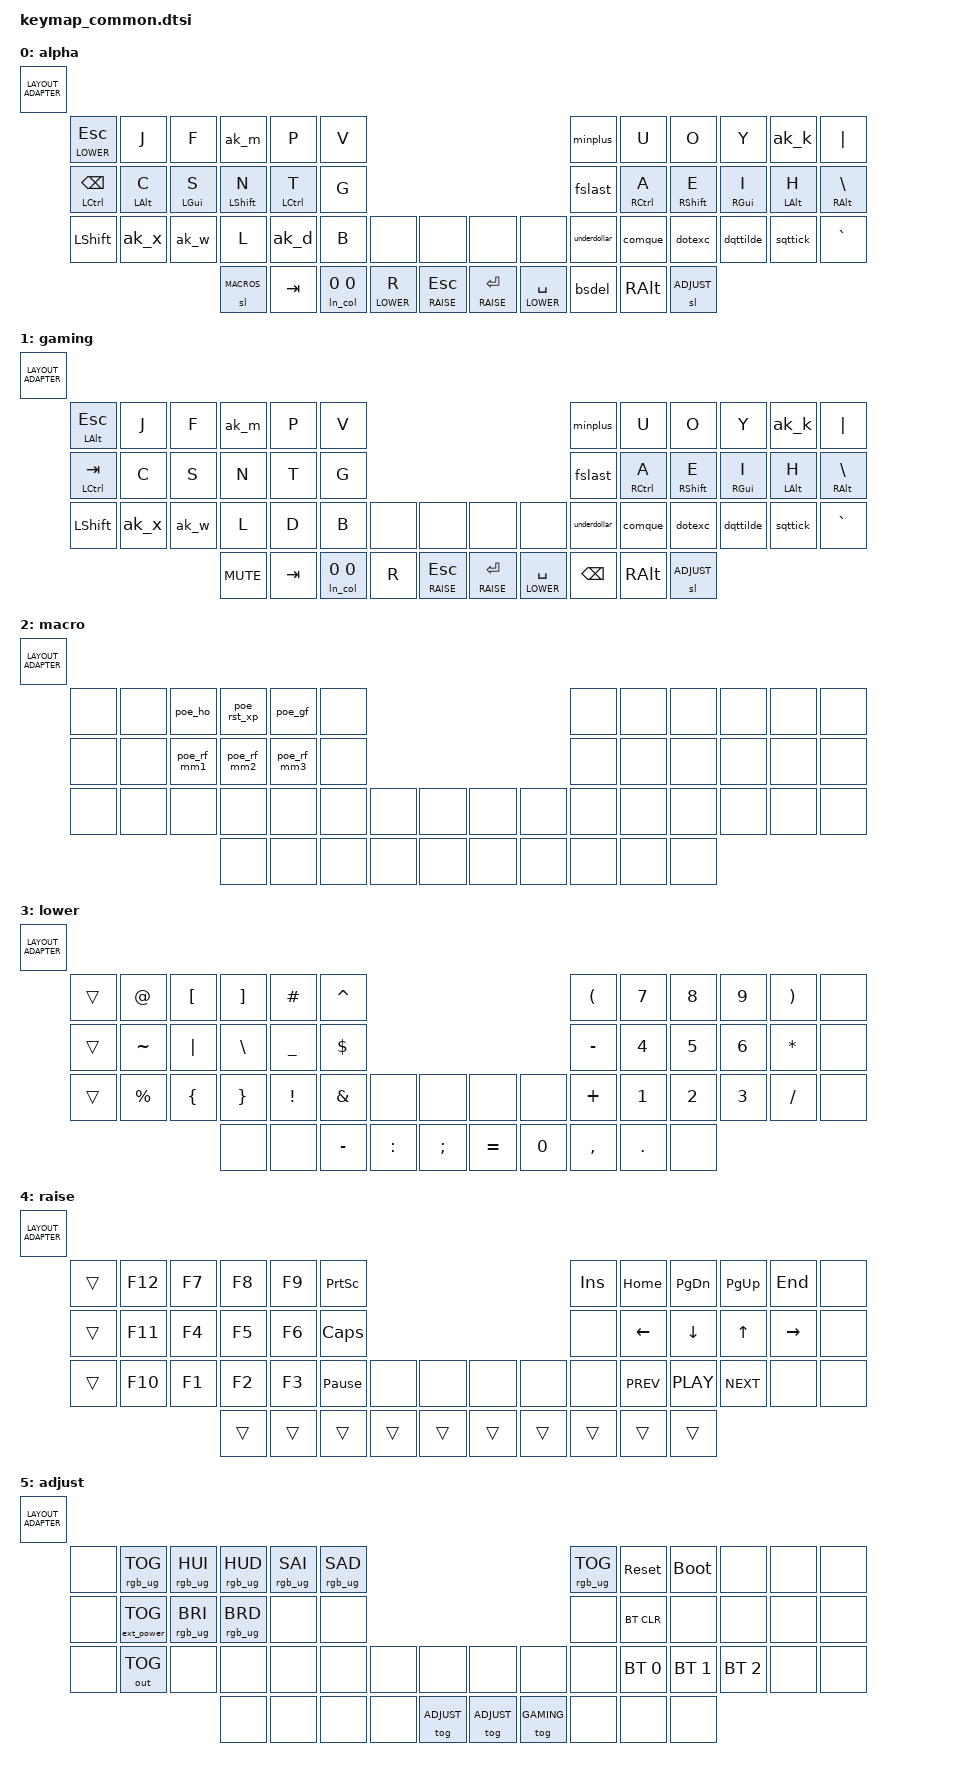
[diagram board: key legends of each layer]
#include "adaptive_keys.dtsi"
#include "behaviors_custom.dtsi"
#include "combos.dtsi"
#include "macros.dtsi"
#include "layer_ids.h"

#include <behaviors.dtsi>
#include <dt-bindings/zmk/bt.h>
#include <dt-bindings/zmk/ext_power.h>
#include <dt-bindings/zmk/keys.h>
#include <dt-bindings/zmk/outputs.h>
#include <dt-bindings/zmk/rgb.h>

// Configure these properties here to ensure they are set after the last time behaviors.dtsi is included, since that
// resets them to their default values.
&mt {
    tapping-term-ms = <170>;
};

&sl {
    release-after-ms = <5000>;
};

/ {
    keymap {
        compatible = "zmk,keymap";

        default_layer {
            display-name = "alpha";
            // -------------------------------------------------------------------------------------------------------------------------------------
            // |   ESC  |  J  |  F  |   M   |  P   |  V   |                                          |  - + |   U   |   O   |  Y   |   K   |   |  |
            // | L CTRL |  C  |  S  |   N   |  T   |  G   |                                          |  / * |   A   |   E   |  I   |   H   |   \  |
            // |  SHIFT |  X  |  W  |   L   |  D   |  B   |  NONE   |   NONE  |  |   NONE  |  NONE   |  _ $ |  , ?  |  . !  |  " ~ |  ' `  | ` ~  |
            //                      | MACROS| TAB  | : ;  |   R     |   ESC   |  |   RET   |  SPACE  | BSPC | R ALT |  NONE |
            bindings = <LAYOUT_ADAPTER(
                &lt LOWER ESC,  &kp J,       &kp F,       &ak_m,        &kp P,        &kp V,                                                                    &minplus,     &kp U,        &kp O,        &kp Y,       &ak_k,       &kp PIPE,
                &mt LCTRL BSPC, &hml LALT C, &hml LGUI S, &hml LSHFT N, &hml LCTRL T, &kp G,                                                                    &fslast,      &hmr RCTRL A, &hmr RSHFT E, &hmr RGUI I, &hmr LALT H, &hmr RALT BSLH,
                &kp LSHFT,      &ak_x,       &ak_w,       &kp L,        &ak_d,        &kp B,       &none,       &none,          &none,         &none,           &underdollar, &comque,      &dotexc,      &dqttilde,   &sqttick,    &kp GRAVE,
                                                          &sl MACROS,   &kp TAB,      &ln_col 0 0, &lt LOWER R, &lt RAISE ESC,  &lt RAISE RET, &lt LOWER SPACE, &bsdel,       &kp RALT,     &sl ADJUST
            )>;

            sensor-bindings = <&inc_dec_kp PG_UP PG_DN &inc_dec_kp C_VOL_DN C_VOL_UP>;
    };

        gaming_layer {
            display-name = "gaming";
            bindings = <LAYOUT_ADAPTER(
                &mt LALT ESC,  &kp J, &kp F, &ak_m,      &kp P,   &kp V,                                                              &minplus,     &kp U,         &kp O,        &kp Y,       &ak_k,       &kp PIPE,
                &mt LCTRL TAB, &kp C, &kp S, &kp N,      &kp T,   &kp G,                                                              &fslast,      &hmr RCTRL A,  &hmr RSHFT E, &hmr RGUI I, &hmr LALT H, &hmr RALT BSLH,
                &kp LSHFT,     &ak_x, &ak_w, &kp L,      &kp D,   &kp B,       &none, &none,          &none,         &none,           &underdollar, &comque,       &dotexc,      &dqttilde,   &sqttick,    &kp GRAVE,
                                             &kp C_MUTE, &kp TAB, &ln_col 0 0, &kp R, &lt RAISE ESC,  &lt RAISE RET, &lt LOWER SPACE, &kp BSPC,     &kp RALT,      &sl ADJUST
            )>;

            sensor-bindings = <&inc_dec_kp PG_UP PG_DN &inc_dec_kp C_VOL_DN C_VOL_UP>;
        };

        macro_layer {
            display-name = "macro";
            bindings = <LAYOUT_ADAPTER(
                &none, &none, &poe_ho,     &poe_rst_xp, &poe_gf,     &none,                              &none, &none, &none, &none, &none, &none,
                &none, &none, &poe_rf_mm1, &poe_rf_mm2, &poe_rf_mm3, &none,                              &none, &none, &none, &none, &none, &none,
                &none, &none, &none,       &none,       &none,       &none, &none, &none,  &none, &none, &none, &none, &none, &none, &none, &none,
                                           &none,       &none,       &none, &none, &none,  &none, &none, &none, &none, &none
            )>;
        };

        lower_layer {
            display-name = "lower";
            bindings = <LAYOUT_ADAPTER(
                &trans, &kp AT,    &kp LBKT, &kp RBKT, &kp HASH,  &kp CARET,                                          &kp LPAR,  &kp N7,  &kp N8, &kp N9, &kp RPAR,  &none,
                &trans, &kp TILDE, &kp PIPE, &kp BSLH, &kp UNDER, &kp DLLR,                                           &kp MINUS, &kp N4,  &kp N5, &kp N6, &kp ASTRK, &none,
                &trans, &kp PRCNT, &kp LBRC, &kp RBRC, &kp EXCL,  &kp AMPS,  &none,     &none,     &none,     &none,  &kp PLUS,  &kp N1,  &kp N2, &kp N3, &kp FSLH,  &none,
                                             &none,    &none,     &kp MINUS, &kp COLON, &kp SEMI,  &kp EQUAL, &kp N0, &kp COMMA, &kp DOT, &none
            )>;

            sensor-bindings = <&inc_dec_kp PG_UP PG_DN &inc_dec_kp C_VOL_DN C_VOL_UP>;
        };

        raise_layer {
            display-name = "raise";
            bindings = <LAYOUT_ADAPTER(
                &trans, &kp F12, &kp F7, &kp F8, &kp F9, &kp PSCRN,                                         &kp INS, &kp HOME,   &kp PG_DN,  &kp PG_UP,  &kp END,   &none,
                &trans, &kp F11, &kp F4, &kp F5, &kp F6, &kp CAPS,                                          &none,   &kp LEFT,   &kp DOWN,   &kp UP,     &kp RIGHT, &none,
                &trans, &kp F10, &kp F1, &kp F2, &kp F3, &kp PAUSE_BREAK, &none,   &none,   &none,  &none,  &none,   &kp C_PREV, &kp C_PLAY, &kp C_NEXT, &none,     &none,
                                         &trans, &trans, &trans,          &trans,  &trans,  &trans, &trans, &trans,  &trans,     &trans
            )>;

            sensor-bindings = <&inc_dec_kp PG_UP PG_DN &inc_dec_kp C_VOL_DN C_VOL_UP>;
        };

        adjust_layer {
            display-name = "adjust";
            bindings = <LAYOUT_ADAPTER(
                &none, &rgb_ug RGB_TOG,   &rgb_ug RGB_HUI, &rgb_ug RGB_HUD, &rgb_ug RGB_SAI, &rgb_ug RGB_SAD,                                                 &rgb_ug RGB_TOG, &sys_reset,   &bootloader,  &none,        &none, &none,
                &none, &ext_power EP_TOG, &rgb_ug RGB_BRI, &rgb_ug RGB_BRD, &none,           &none,                                                           &none,           &bt BT_CLR,   &none,        &none,        &none, &none,
                &none, &out OUT_TOG,      &none,           &none,           &none,           &none,           &none, &none,        &none,       &none,        &none,           &bt BT_SEL 0, &bt BT_SEL 1, &bt BT_SEL 2, &none, &none,
                                                           &none,           &none,           &none,           &none, &tog ADJUST,  &tog ADJUST, &tog GAMING,  &none,           &none,        &none
            )>;

            sensor-bindings = <&inc_dec_kp PG_UP PG_DN &inc_dec_kp C_VOL_DN C_VOL_UP>;
        };
    };
};
